# M3H0 register map
File version: 0.1
Registers are 32-bit, read-write, reset 0x0 unless marked. A register's access mark holds for its fields unless they carry their own. Offsets are from the block's base; [hi:lo] are bit positions; {n}, {i} and the like mark numbered series.

## PD — Port D
Base 0x400C0300
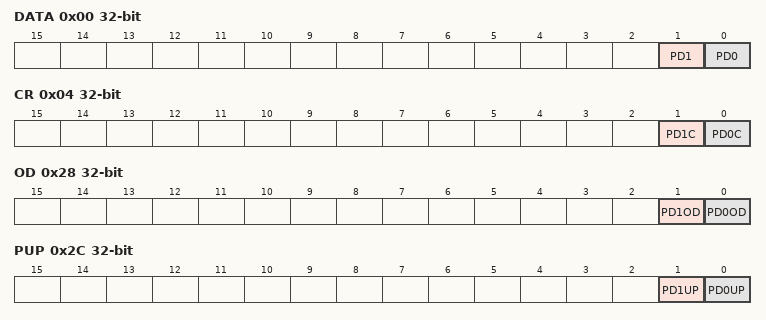
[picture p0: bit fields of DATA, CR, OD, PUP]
0x00 DATA — PD Data Register
  [1] PD1, [0] PD0
0x04 CR — PD Control Register
  [1] PD1C, [0] PD0C
0x28 OD — PD Open Drain Control Register
  [1] PD1OD, [0] PD0OD
0x2C PUP — PD Pull-up Control Register
  [1] PD1UP, [0] PD0UP
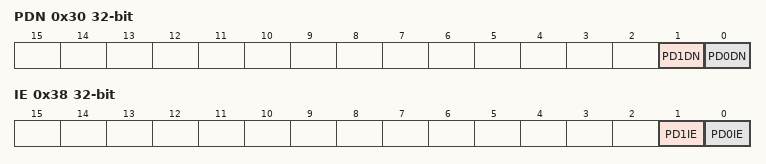
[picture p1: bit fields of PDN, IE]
0x30 PDN — PD Pull-Down Control Register
  [1] PD1DN, [0] PD0DN
0x38 IE — PD Input Enable Control Register
  [1] PD1IE, [0] PD0IE

## PE — Port E
Base 0x400C0400
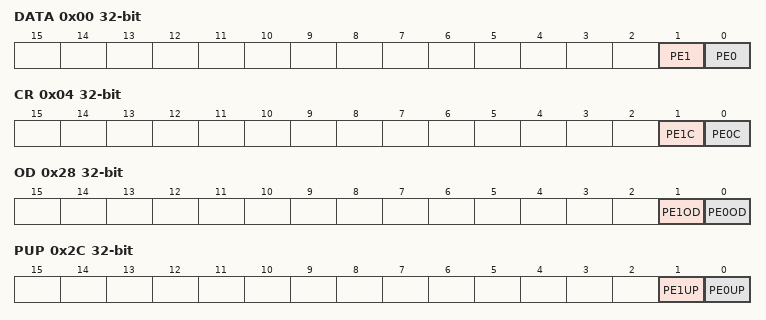
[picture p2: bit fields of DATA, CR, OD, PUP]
0x00 DATA — PE Data Register
  [1] PE1, [0] PE0
0x04 CR — PE Control Register
  [1] PE1C, [0] PE0C
0x28 OD — PE Open Drain Control Register
  [1] PE1OD, [0] PE0OD
0x2C PUP — PE Pull-up Control Register
  [1] PE1UP, [0] PE0UP
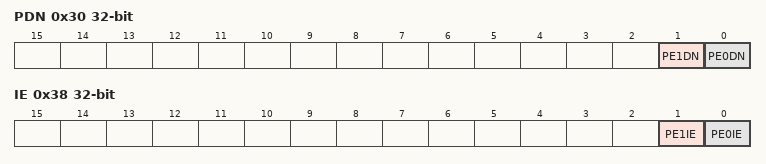
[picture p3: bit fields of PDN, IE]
0x30 PDN — PE Pull-Down Control Register
  [1] PE1DN, [0] PE0DN
0x38 IE — PE Input Enable Control Register
  [1] PE1IE, [0] PE0IE

## PH
Base 0x400C0700
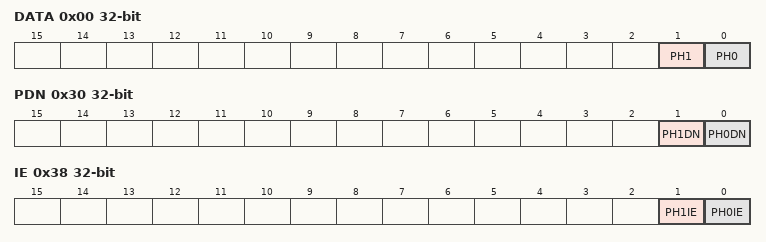
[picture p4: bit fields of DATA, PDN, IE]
0x00 DATA — PH Data Register
  [1] PH1, [0] PH0
0x30 PDN — PH Pull-Down Control Register
  [1] PH1DN, [0] PH0DN
0x38 IE — PH Input Enable Control Register
  [1] PH1IE, [0] PH0IE

## PJ
Base 0x400C0800
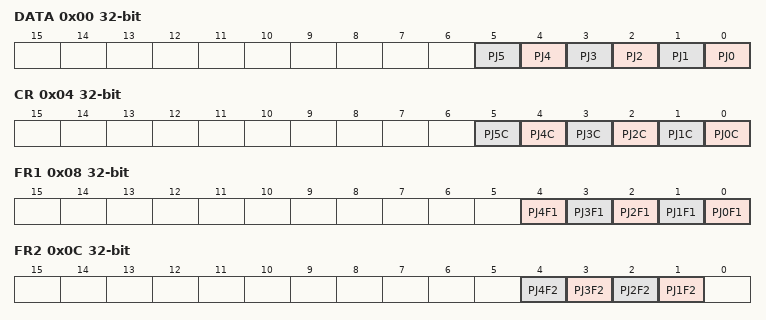
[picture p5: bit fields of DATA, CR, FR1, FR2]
0x00 DATA — PJ Data Register
  [n] PJ{n} (n=0..5)
0x04 CR — PJ Control Register
  [n] PJ{n}C (n=0..5)
0x08 FR1 — PJ Function Register 1
  [n] PJ{n}F1 (n=0..4)
0x0C FR2 — PJ Function Register 2
  [n] PJ{n}F2 (n=1..4)
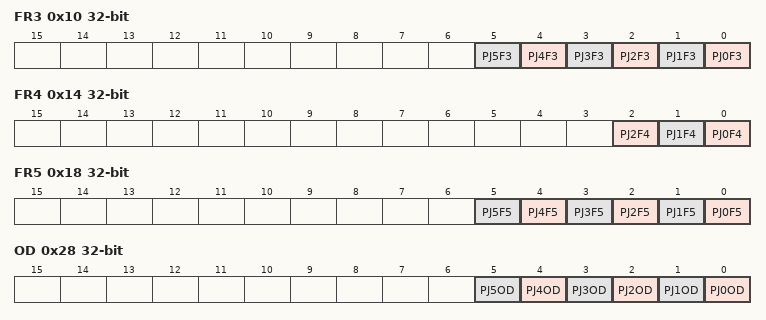
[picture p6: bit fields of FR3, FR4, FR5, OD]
0x10 FR3 — PJ Function Register 3
  [n] PJ{n}F3 (n=0..5)
0x14 FR4 — PJ Function Register 4
  [2] PJ2F4, [1] PJ1F4, [0] PJ0F4
0x18 FR5 — PJ Function Register 5
  [n] PJ{n}F5 (n=0..5)
0x28 OD — PJ Open Drain Control Register
  [n] PJ{n}OD (n=0..5)
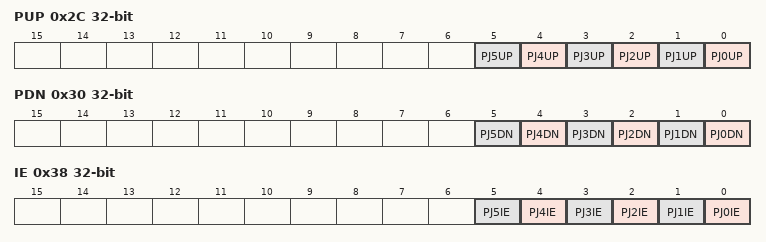
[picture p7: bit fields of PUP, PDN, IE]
0x2C PUP — PJ Pull-up Control Register
  [n] PJ{n}UP (n=0..5)
0x30 PDN — PJ Pull-Down Control Register
  [n] PJ{n}DN (n=0..5)
0x38 IE — PJ Input Enable Control Register
  [n] PJ{n}IE (n=0..5)

## PK
Base 0x400C0900
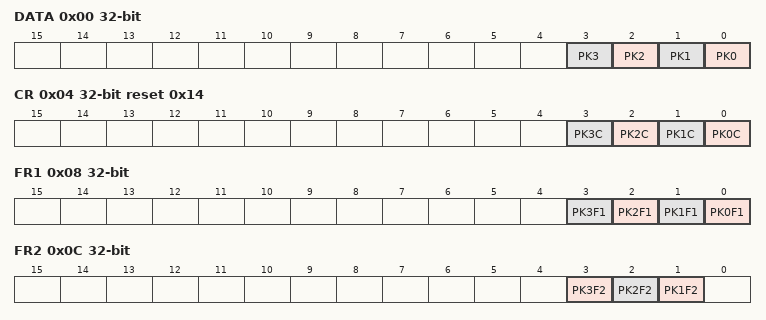
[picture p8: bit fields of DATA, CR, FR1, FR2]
0x00 DATA — PK Data Register
  [n] PK{n} (n=0..3)
0x04 CR reset 0x14 — PK Control Register
  [n] PK{n}C (n=0..3)
0x08 FR1 — PK Function Register 1
  [n] PK{n}F1 (n=0..3)
0x0C FR2 — PK Function Register 2
  [3] PK3F2, [2] PK2F2, [1] PK1F2
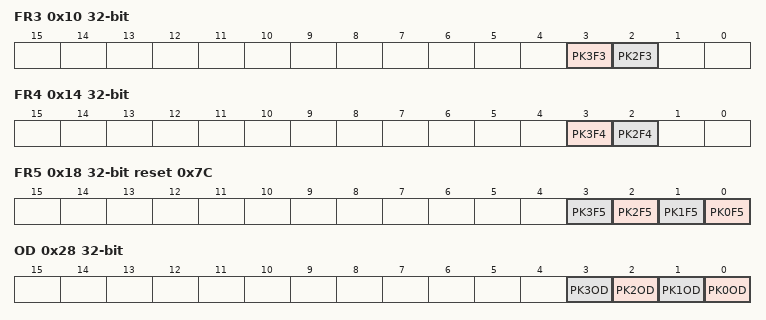
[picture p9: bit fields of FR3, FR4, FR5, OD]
0x10 FR3 — PK Function Register 3
  [3] PK3F3, [2] PK2F3
0x14 FR4 — PK Function Register 4
  [3] PK3F4, [2] PK2F4
0x18 FR5 reset 0x7C — PK Function Register 5
  [n] PK{n}F5 (n=0..3)
0x28 OD — PK Open Drain Control Register
  [n] PK{n}OD (n=0..3)
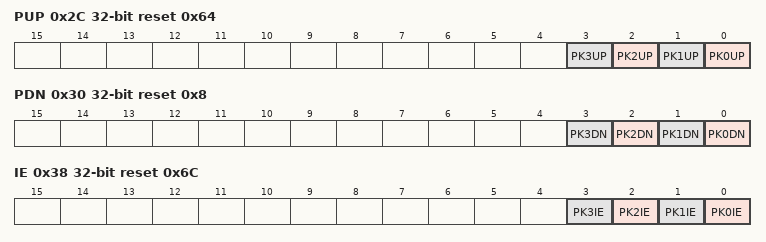
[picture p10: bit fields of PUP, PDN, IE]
0x2C PUP reset 0x64 — PK Pull-up Control Register
  [n] PK{n}UP (n=0..3)
0x30 PDN reset 0x8 — PK Pull-Down Control Register
  [n] PK{n}DN (n=0..3)
0x38 IE reset 0x6C — PK Input Enable Control Register
  [n] PK{n}IE (n=0..3)

## OFD
Base 0x400F1000
0x00 CR1 reset 0x6 — OFD Control Register 1
  [7:0] OFDWEN
0x04 CR2 — OFD Control Register 2
  [7:0] OFDEN
0x08 MN0 — OFD Lower Detection Frequency Setting Register0
  [11:0] OFDMN0
0x0C MN1 — OFD Lower Detection Frequency Setting Register1
  [11:0] OFDMN1
0x10 MX0 — OFD Higher Detection Frequency Setting Register0
  [11:0] OFDMX0
0x14 MX1 — OFD Higher Detection Frequency Setting Register1
  [11:0] OFDMX1
0x18 RST reset 0x1 — OFD Reset Enable Control Register
  [0] OFDRSTEN
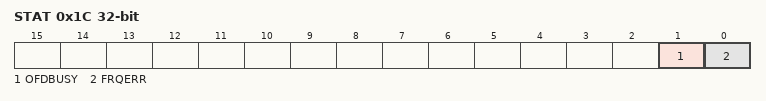
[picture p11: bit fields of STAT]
0x1C STAT ro — OFD Status Register
  [1] OFDBUSY, [0] FRQERR
0x20 MON reset 0x1 — OFD External high frequency oscillaion clock monitor register
  [0] OFDMON

## CG
Base 0x400F3000
0x00 PROTECT reset 0xC1 — CG Protect Register
  [7:0] PROTECT
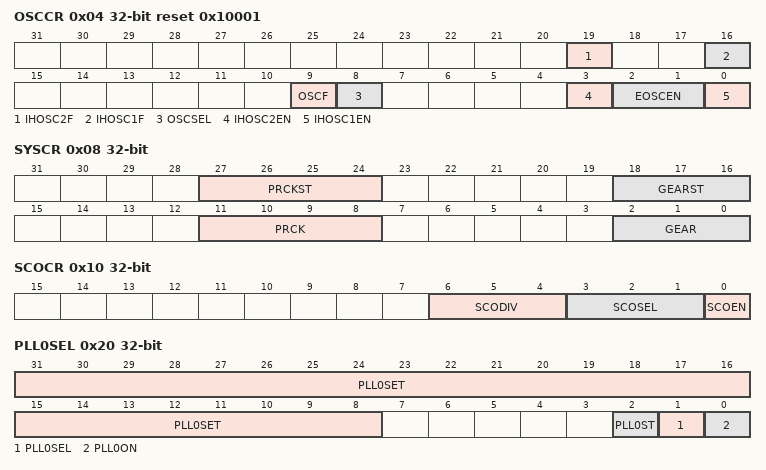
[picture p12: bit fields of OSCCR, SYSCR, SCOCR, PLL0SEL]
0x04 OSCCR reset 0x10001 — CG Oscillation Control Register
  [19] IHOSC2F ro, [16] IHOSC1F ro, [9] OSCF ro, [8] OSCSEL, [3] IHOSC2EN, [2:1] EOSCEN, [0] IHOSC1EN
0x08 SYSCR — CG System clock control register
  [27:24] PRCKST ro, [18:16] GEARST ro, [11:8] PRCK, [2:0] GEAR
0x0C STBYCR — CG Standby Control Register
  [1:0] STBY
0x10 SCOCR — CG SCOUT Control Register
  [6:4] SCODIV, [3:1] SCOSEL, [0] SCOEN
0x20 PLL0SEL — CG PLL select register for fsys
  [31:8] PLL0SET, [2] PLL0ST ro, [1] PLL0SEL, [0] PLL0ON
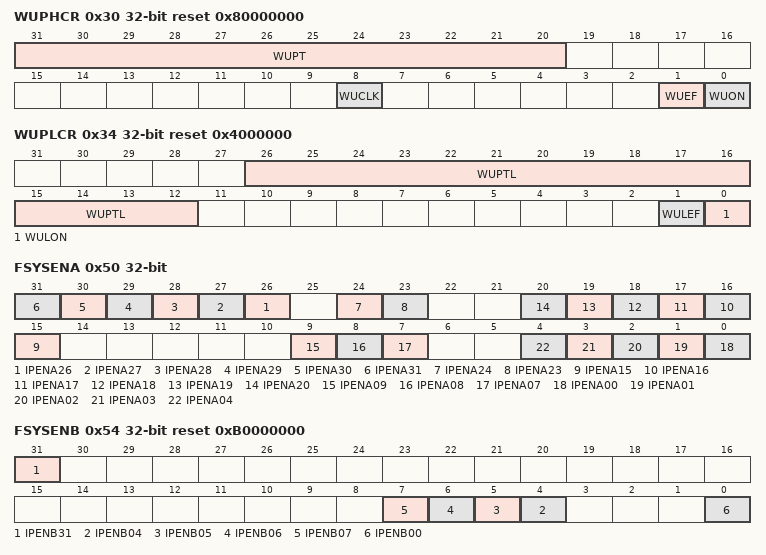
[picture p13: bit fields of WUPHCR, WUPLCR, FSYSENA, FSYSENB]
0x30 WUPHCR reset 0x80000000 — CG Warmup register for HOSC
  [31:20] WUPT, [8] WUCLK, [1] WUEF ro, [0] WUON wo
0x34 WUPLCR reset 0x4000000 — CG Low-speed oscillation warm-up register
  [26:12] WUPTL, [1] WULEF ro, [0] WULON wo
0x50 FSYSENA — CG output control register A for fsys clock
  [n] IPENA{n} (n=26..31), [24] IPENA24, [23] IPENA23, [n] IPENA{n} (n=15..20), [9] IPENA09, [8] IPENA08, [7] IPENA07, [n] IPENA{n:02} (n=0..4)
0x54 FSYSENB reset 0xB0000000 (reset mask 0x7FFFFFFF) — CG output control register B for fsys clock
  [31] IPENB31, [n] IPENB{n:02} (n=4..7), [0] IPENB00
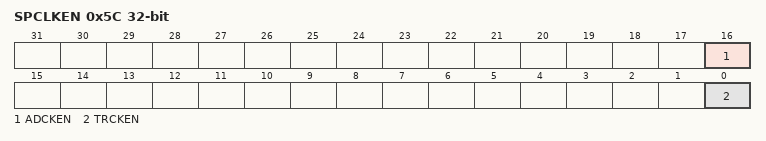
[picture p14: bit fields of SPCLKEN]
0x5C SPCLKEN — CG Output control register for ADC AND TRACE CLOCK
  [16] ADCKEN, [0] TRCKEN
